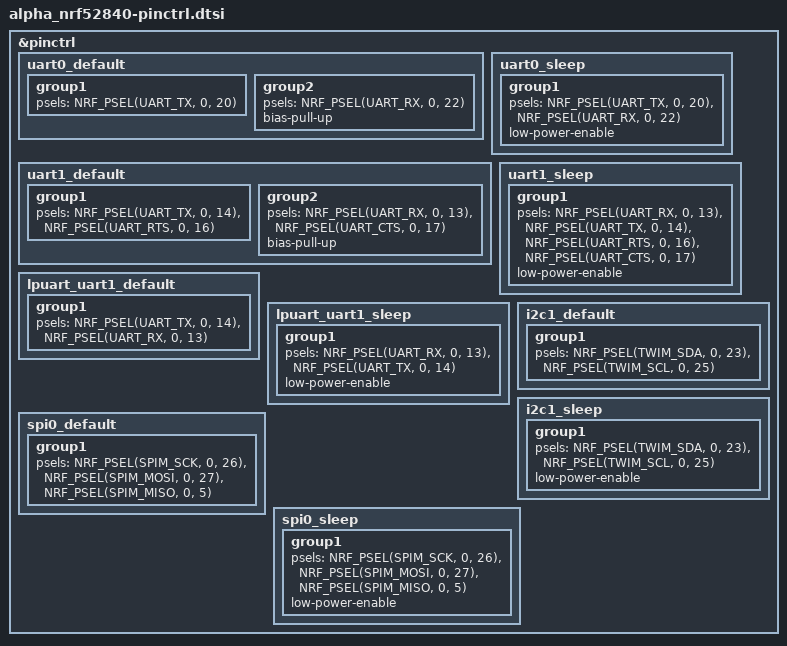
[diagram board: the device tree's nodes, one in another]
&pinctrl {
    uart0_default: uart0_default {
        group1 {
            psels = <NRF_PSEL(UART_TX, 0, 20)>;
        };
        group2 {
            psels = <NRF_PSEL(UART_RX, 0, 22)>;
            bias-pull-up;
        };
    };

    uart0_sleep: uart0_sleep {
        group1 {
            psels = <NRF_PSEL(UART_TX, 0, 20)>,
                    <NRF_PSEL(UART_RX, 0, 22)>;
            low-power-enable;
        };
    };

    uart1_default: uart1_default {
        group1 {
            psels = <NRF_PSEL(UART_TX, 0, 14)>,
                    <NRF_PSEL(UART_RTS, 0, 16)>;
        };
        group2 {
            psels = <NRF_PSEL(UART_RX, 0, 13)>,
                    <NRF_PSEL(UART_CTS, 0, 17)>;
            bias-pull-up;
        };
    };

    uart1_sleep: uart1_sleep {
        group1 {
            psels = <NRF_PSEL(UART_RX, 0, 13)>,
                    <NRF_PSEL(UART_TX, 0, 14)>,
                    <NRF_PSEL(UART_RTS, 0, 16)>,
                    <NRF_PSEL(UART_CTS, 0, 17)>;
            low-power-enable;
        };
    };

    lpuart_uart1_default: lpuart_uart1_default {
        group1 {
            psels = <NRF_PSEL(UART_TX, 0, 14)>,
                    <NRF_PSEL(UART_RX, 0, 13)>;
        };
    };

    lpuart_uart1_sleep: lpuart_uart1_sleep {
        group1 {
            psels = <NRF_PSEL(UART_RX, 0, 13)>,
                    <NRF_PSEL(UART_TX, 0, 14)>;
            low-power-enable;
        };
    };

    i2c1_default: i2c1_default {
        group1 {
            psels = <NRF_PSEL(TWIM_SDA, 0, 23)>,
                    <NRF_PSEL(TWIM_SCL, 0, 25)>;
        };
    };

    i2c1_sleep: i2c1_sleep {
        group1 {
            psels = <NRF_PSEL(TWIM_SDA, 0, 23)>,
                    <NRF_PSEL(TWIM_SCL, 0, 25)>;
            low-power-enable;
        };
    };

    spi0_default: spi0_default {
        group1 {
            psels = <NRF_PSEL(SPIM_SCK, 0, 26)>,
                    <NRF_PSEL(SPIM_MOSI, 0, 27)>,
                    <NRF_PSEL(SPIM_MISO, 0, 5)>;
        };
    };

    spi0_sleep: spi0_sleep {
        group1 {
            psels = <NRF_PSEL(SPIM_SCK, 0, 26)>,
                    <NRF_PSEL(SPIM_MOSI, 0, 27)>,
                    <NRF_PSEL(SPIM_MISO, 0, 5)>;
            low-power-enable;
        };
    };
};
